# RZN2H register map
Vendor: Renesas Electronics Corporation; Series: RZN; File version: 1.00.00
CPU: other r0p0, little endian, MPU, no FPU, VTOR, 4 interrupt priority bits, 624 interrupts
Registers are 32-bit, read-write, reset 0x0 unless marked. A register's access mark holds for its fields unless they carry their own. Offsets are from the block's base; [hi:lo] are bit positions; {n}, {i} and the like mark numbered series; 'fields as' and 'values as' point back to an identical list.

## MPU10 — Master MPU 10
Base 0x81290400
Same registers: MPU11 0x81290500, MPU12 0x81290600, MPU13 0x81290700, MPU0 0x81291400, MPU1 0x81291500, MPU4 0x81291800, MPU5 0x81291900, MPU6 0x81291A00
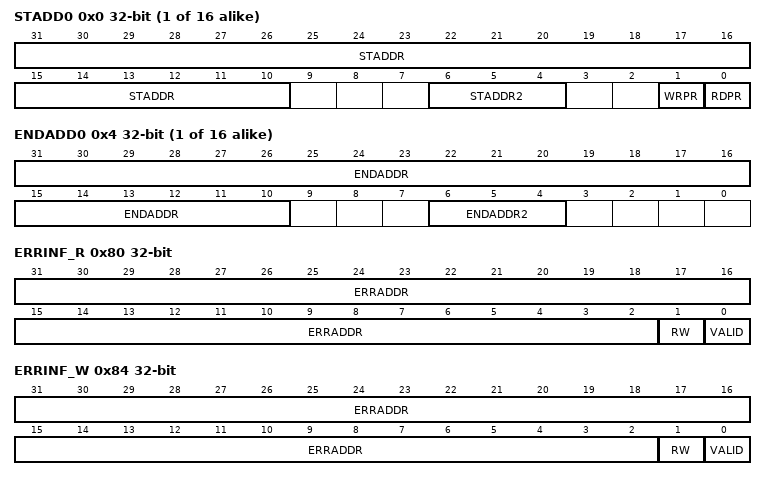
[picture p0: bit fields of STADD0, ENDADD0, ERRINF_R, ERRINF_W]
{0x0+8i} STADD{i} (i=0..15) (reset mask 0xFFFFFFFC) — Master MPU Safety Region Start Address Register {i}
  [31:10] STADDR — Start address for MPU region
  [6:4] STADDR2 — Start address for MPU region
  [1] WRPR
    0=Disable write protection. Write access to the safety region is permitted.; 1=Enable write protection. Write access to the safety region is protected and error is generated.
  [0] RDPR
    0=Disable read protection. Read access to the safety region is permitted.; 1=Enable read protection. Read access to the safety region is protected and error is generated.
{0x4+8i} ENDADD{i} (i=0..15) (reset mask 0x38F) — Master MPU Safety Region End Address Register {i}
  [31:10] ENDADDR — End address for MPU region
  [6:4] ENDADDR2 — End address for MPU region
0x80 ERRINF_R — Master MPU Error Information Register for AXI type
  [31:2] ERRADDR ro — Access error address
  [1] RW ro
    0=Read access; 1=Write access
  [0] VALID — Cleared to 0 when 0 is written.
    0=Error information is invalid; 1=Error information is valid
0x84 ERRINF_W — Master MPU Error Information Register for AXI type
  fields as ERRINF_R

## MPU14 — Master MPU 14
Base 0x81290800
Same registers: MPU2 0x81291600, MPU3 0x81291700
Registers as MPU10, without ERRINF_R, ERRINF_W; these are added or differ:
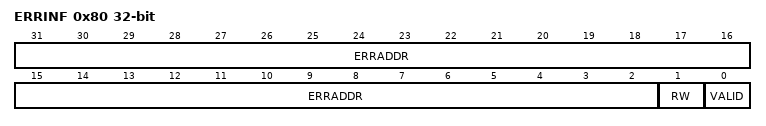
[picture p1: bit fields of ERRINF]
0x80 ERRINF — Master MPU Error Information Register for AHB type
  [31:2] ERRADDR ro — Indicates upper 30 bits of the 32-bit address. Lower 2 bits are masked.
  [1] RW ro
    0=Read access; 1=Write access
  [0] VALID — Cleared to 0 when 0 is written.
    0=Error information is invalid; 1=Error information is valid

## MPU15 — Master MPU 15
Base 0x81290900
Same registers: MPU7 0x81291B00, MPU8 0x81291C00, MPU9 0x81291D00
Registers as MPU10; these are added or differ:
0x88 ERRINF1_R ro — Master MPU Error Information Register for AXI type 1
  [2:0] ERRADDR2
0x8C ERRINF1_W ro — Master MPU Error Information Register for AXI type 1
  [2:0] ERRADDR2

## ADXC1 — Address Expander Control 1
Base 0x81291100
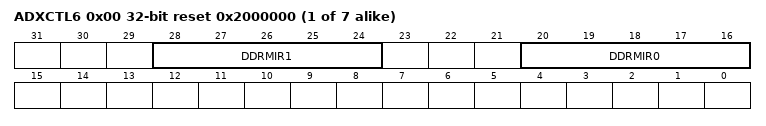
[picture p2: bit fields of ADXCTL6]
0x00 ADXCTL{i} (i=6..12; step 0x4) reset 0x2000000 — Address Expander Control Register {i}
  [28:24] DDRMIR1 — DDR Mirror Address 1
  [20:16] DDRMIR0 — DDR Mirror Address 0

## SYSRAM_CTL — System SRAM Control
Base 0x81293000
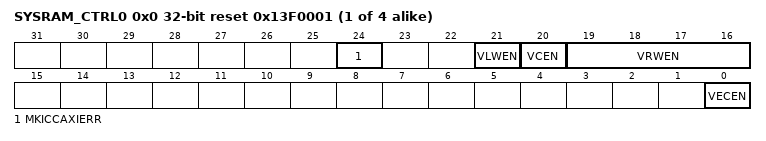
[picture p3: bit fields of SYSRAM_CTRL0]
{0x0+0x10*i} SYSRAM_CTRL{i} (i=0..3) reset 0x13F0001 — System SRAM Control Register {i}
  [24] MKICCAXIERR — Controls AXI-SLVERR issuance for ECC 2-bit errors
    0=Issue AXI-SLEVER; 1=Do not issue AXI-SLEVER
  [21] VLWEN — Enables write for RAM
    0=Disabled; 1=Enabled
  [20] VCEN — Enables access to RAM
    0=Disabled; 1=Enabled
  [19:16] VRWEN — Enables write for each page of RAM
    0=Disabled; 1=Enabled
  [0] VECEN — Enables or disables error correction with ECC
    0=Disabled; 1=Enabled

## SHOSTIF_CFG
Base 0x81294000
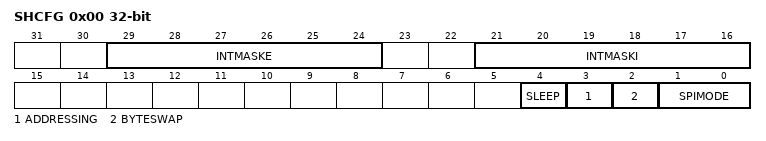
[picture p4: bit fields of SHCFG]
0x00 SHCFG
  [29:24] INTMASKE, [21:16] INTMASKI, [4] SLEEP ro, [3] ADDRESSING, [2] BYTESWAP, [1:0] SPIMODE

## TCMAW — TCM access wait state
Base 0x81295000
0x08 CPU0WAIT ro (reset mask 0xFFFFFFFE) — CPU0 ATCM Wait State Register
  [0] CPU0WAIT — ATCM Wait state
    0=0-wait state (MDW0 = 0); 1=1-wait state (MDW0 = 1)
0x0C CPU1WAIT ro (reset mask 0xFFFFFFFE) — CPU1 ATCM Wait State Register
  [0] CPU1WAIT
    0=0-wait state (MDW1 = 0); 1=1-wait state (MDW1 = 1)
0x10 CPU1HALT reset 0x1 — CPU1 HALT Control Register
  [0] CPU1HALT
    0=Start instruction fetch; 1=Stop instruction fetch
